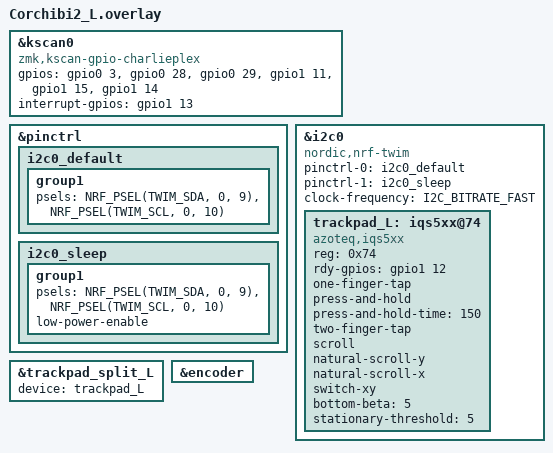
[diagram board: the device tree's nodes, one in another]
#include "corchibi2.dtsi"
#include <dt-bindings/pinctrl/nrf-pinctrl.h>
#include <dt-bindings/zmk/input_transform.h>
#include <input/processors.dtsi>

&kscan0 {
    compatible = "zmk,kscan-gpio-charlieplex";
    gpios
        = <&gpio0 3 (GPIO_ACTIVE_HIGH)>
        , <&gpio0 28 (GPIO_ACTIVE_HIGH)>
        , <&gpio0 29 (GPIO_ACTIVE_HIGH)>
        , <&gpio1 11 (GPIO_ACTIVE_HIGH)>
        , <&gpio1 15 (GPIO_ACTIVE_HIGH)>
        , <&gpio1 14 (GPIO_ACTIVE_HIGH)>
        ;
    interrupt-gpios = <&gpio1 13 (GPIO_ACTIVE_HIGH | GPIO_PULL_DOWN)>;
};

&pinctrl {
    i2c0_default: i2c0_default {
        group1 {
            psels = <NRF_PSEL(TWIM_SDA, 0, 9)>,
                    <NRF_PSEL(TWIM_SCL, 0, 10)>;
        };
    };

    i2c0_sleep: i2c0_sleep {
        group1 {
            psels = <NRF_PSEL(TWIM_SDA, 0, 9)>,
                    <NRF_PSEL(TWIM_SCL, 0, 10)>;
            low-power-enable;
        };
    };
};

&i2c0 {
    status = "okay";
    compatible = "nordic,nrf-twim";
    pinctrl-0 = <&i2c0_default>;
    pinctrl-1 = <&i2c0_sleep>;
    pinctrl-names = "default", "sleep";
    clock-frequency = <I2C_BITRATE_FAST>;
    #address-cells = <1>;
    #size-cells = <0>;

    trackpad_L: iqs5xx@74 {
        compatible = "azoteq,iqs5xx";
        status = "okay";
        reg = <0x74>;

        rdy-gpios = <&gpio1 12 (GPIO_ACTIVE_HIGH | GPIO_PULL_DOWN)>;
        /* RST shares the old PAW3222 NCS connector position and is intentionally unconnected. */

        one-finger-tap;
        press-and-hold;
        press-and-hold-time = <150>;
        two-finger-tap;
        scroll;
        natural-scroll-y;
        natural-scroll-x;
        switch-xy;
        bottom-beta = <5>;
        stationary-threshold = <5>;
    };
};

&trackpad_split_L {
    status = "okay";
    device = <&trackpad_L>;
};

&encoder {
    status = "okay";
};
